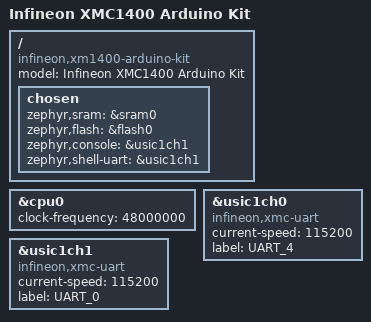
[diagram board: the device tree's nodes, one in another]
/*
 * SPDX-License-Identifier: Apache-2.0
 *
 * Copyright (c) 2021 Linumiz
 * Author: Parthiban Nallathambi <parthiban@linumiz.com>
 *
 */

/dts-v1/;

#include <infineon/xmc1400.dtsi>

/ {
	model = "Infineon XMC1400 Arduino Kit";
	compatible = "infineon,xm1400-arduino-kit", "infineon,xmc1400",
						"infineon,xmc1xxx";

	chosen {
		zephyr,sram = &sram0;
		zephyr,flash = &flash0;
		zephyr,console = &usic1ch1;
		zephyr,shell-uart = &usic1ch1;
	};
};

&cpu0 {
	clock-frequency = <48000000>;
};

&usic1ch0 {
	compatible = "infineon,xmc-uart";
	current-speed = <115200>;
	label = "UART_4";
	status = "okay";
};

&usic1ch1 {
	compatible = "infineon,xmc-uart";
	current-speed = <115200>;
	label = "UART_0";
	status = "okay";
};
